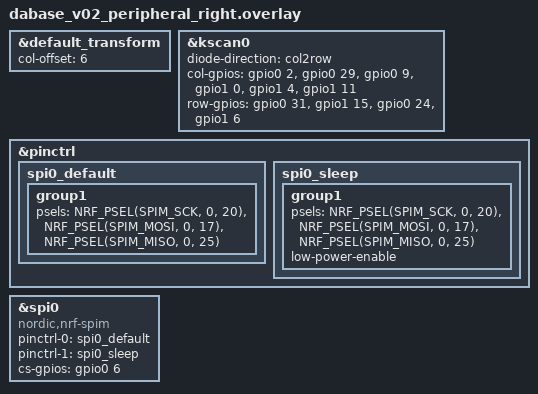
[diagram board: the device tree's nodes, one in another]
#include "dabase_v02.dtsi"

&default_transform {
    col-offset = <6>;
};

&kscan0 {
    diode-direction = "col2row";
    col-gpios
        = <&gpio0 2  GPIO_ACTIVE_HIGH>
        , <&gpio0 29 GPIO_ACTIVE_HIGH>
        , <&gpio0 9  GPIO_ACTIVE_HIGH>
        , <&gpio1 0  GPIO_ACTIVE_HIGH>
        , <&gpio1 4  GPIO_ACTIVE_HIGH>
        , <&gpio1 11 GPIO_ACTIVE_HIGH>
    ;

    row-gpios
        = <&gpio0 31 (GPIO_ACTIVE_HIGH | GPIO_PULL_DOWN)>
        , <&gpio1 15 (GPIO_ACTIVE_HIGH | GPIO_PULL_DOWN)>
        , <&gpio0 24 (GPIO_ACTIVE_HIGH | GPIO_PULL_DOWN)>
        , <&gpio1 6  (GPIO_ACTIVE_HIGH | GPIO_PULL_DOWN)>
    ;
};

&pinctrl {
    spi0_default: spi0_default {
        group1 {
            psels = <NRF_PSEL(SPIM_SCK, 0, 20)>,
                <NRF_PSEL(SPIM_MOSI, 0, 17)>,
                <NRF_PSEL(SPIM_MISO, 0, 25)>;
        };
    };

    spi0_sleep: spi0_sleep {
        group1 {
            psels = <NRF_PSEL(SPIM_SCK, 0, 20)>,
                <NRF_PSEL(SPIM_MOSI, 0, 17)>,
                <NRF_PSEL(SPIM_MISO, 0, 25)>;
            low-power-enable;
        };
    };
};

nice_view_spi: &spi0 {
    compatible = "nordic,nrf-spim";
    pinctrl-0 = <&spi0_default>;
    pinctrl-1 = <&spi0_sleep>;
    pinctrl-names = "default", "sleep";
    cs-gpios = <&gpio0 6 GPIO_ACTIVE_HIGH>;
};
